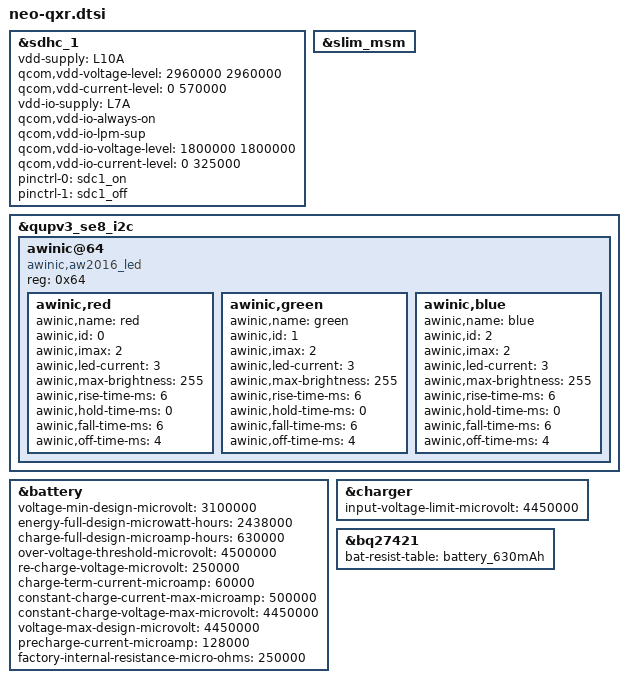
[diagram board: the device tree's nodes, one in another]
#include "neo-pmic-overlay.dtsi"
#include "neo-thermal-overlay.dtsi"

&sdhc_1 {
	status = "ok";

	vdd-supply = <&L10A>;
	qcom,vdd-voltage-level = <2960000 2960000>;
	qcom,vdd-current-level = <0 570000>;

	vdd-io-supply = <&L7A>;
	qcom,vdd-io-always-on;
	qcom,vdd-io-lpm-sup;
	qcom,vdd-io-voltage-level = <1800000 1800000>;
	qcom,vdd-io-current-level = <0 325000>;

	pinctrl-names = "default", "sleep";
	pinctrl-0 = <&sdc1_on>;
	pinctrl-1 = <&sdc1_off>;
};


&slim_msm {
	status = "ok";
};

&qupv3_se8_i2c {
	awinic@64 {
		compatible = "awinic,aw2016_led";
		reg = <0x64>;

		awinic,red {
			awinic,name = "red";
			awinic,id = <0>;
			awinic,imax = <2>;
			awinic,led-current = <3>;
			awinic,max-brightness = <255>;
			awinic,rise-time-ms = <6>;
			awinic,hold-time-ms = <0>;
			awinic,fall-time-ms = <6>;
			awinic,off-time-ms = <4>;
		};

		awinic,green {
			awinic,name = "green";
			awinic,id = <1>;
			awinic,imax = <2>;
			awinic,led-current = <3>;
			awinic,max-brightness = <255>;
			awinic,rise-time-ms = <6>;
			awinic,hold-time-ms = <0>;
			awinic,fall-time-ms = <6>;
			awinic,off-time-ms = <4>;
		};

		awinic,blue {
			awinic,name = "blue";
			awinic,id = <2>;
			awinic,imax = <2>;
			awinic,led-current = <3>;
			awinic,max-brightness = <255>;
			awinic,rise-time-ms = <6>;
			awinic,hold-time-ms = <0>;
			awinic,fall-time-ms = <6>;
			awinic,off-time-ms = <4>;
		};
	};
};


&battery {
	voltage-min-design-microvolt = <3100000>;
	energy-full-design-microwatt-hours = <2438000>;
	charge-full-design-microamp-hours = <630000>;
	over-voltage-threshold-microvolt = <4500000>;
	re-charge-voltage-microvolt = <250000>;
	/* bq256xx's termination current setting has a min limit of 60mA */
	charge-term-current-microamp = <60000>;
	constant-charge-current-max-microamp = <500000>;
	constant-charge-voltage-max-microvolt = <4450000>;
	voltage-max-design-microvolt = <4450000>;
	precharge-current-microamp = <128000>;
	factory-internal-resistance-micro-ohms = <250000>;
};

&charger {
	input-voltage-limit-microvolt = <4450000>;
};

&bq27421 {
	bat-resist-table = <&battery_630mAh>;
};
